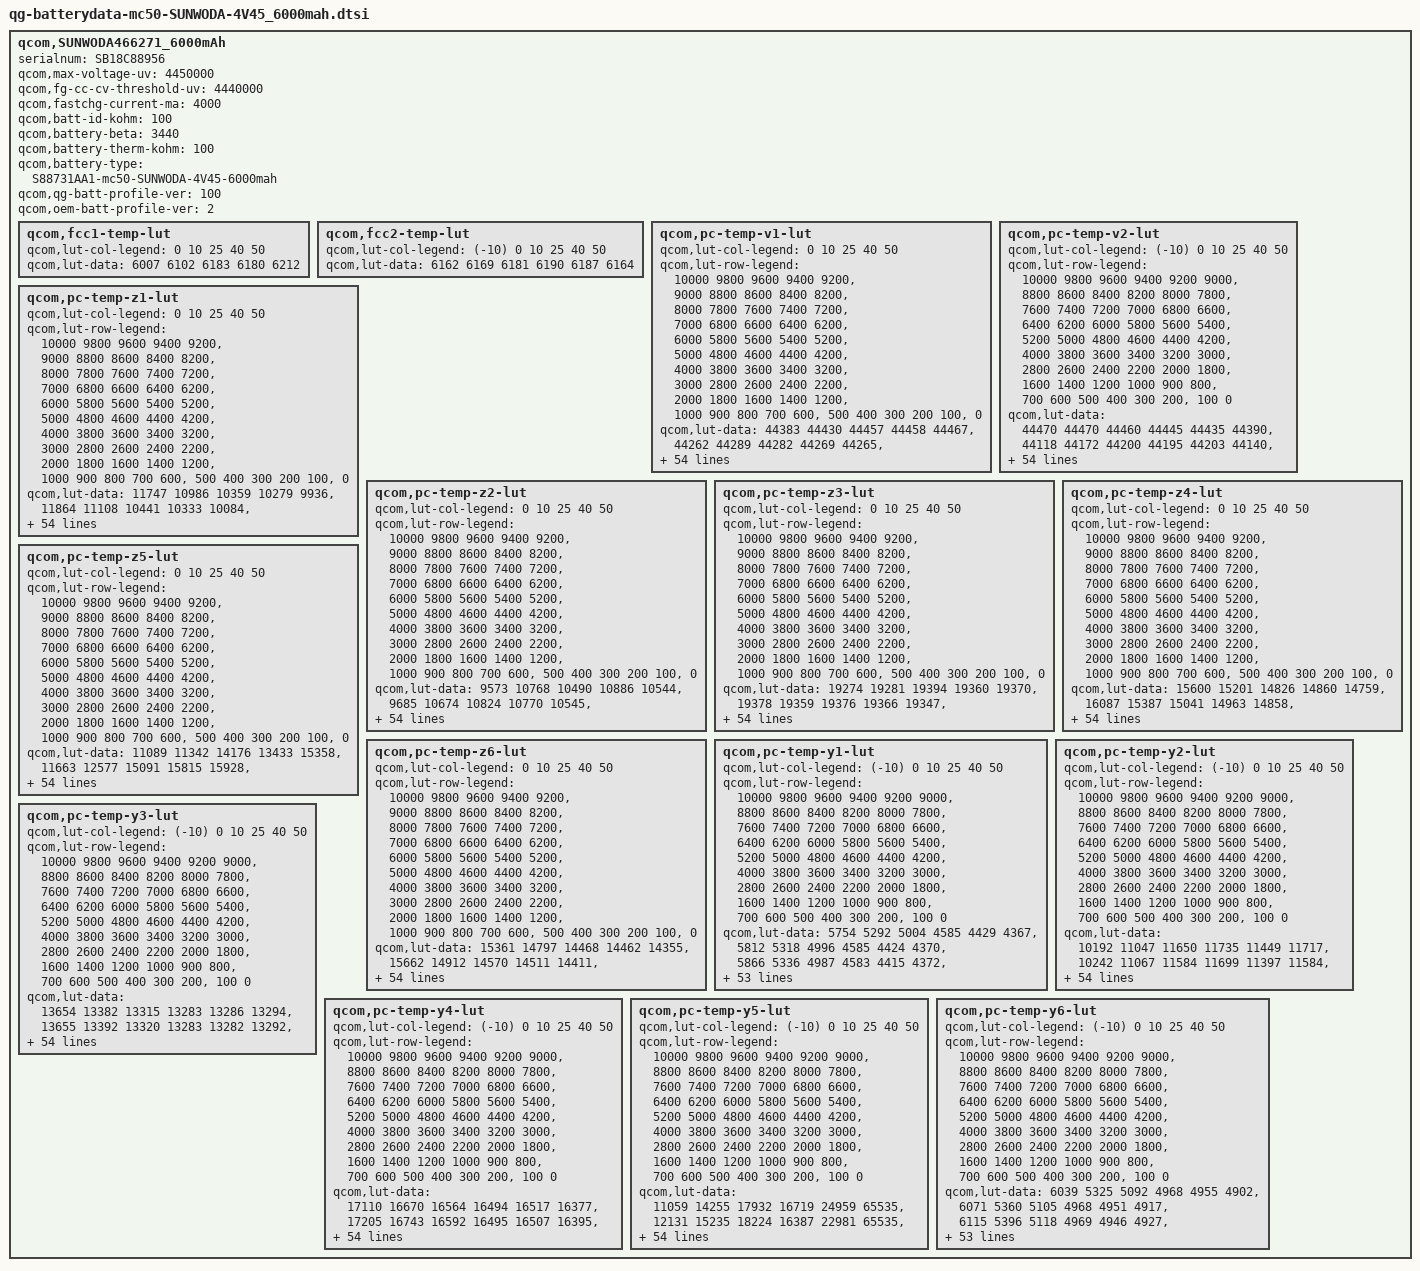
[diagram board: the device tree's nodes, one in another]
qcom,SUNWODA466271_6000mAh {
	/* SUNWODA466271_6000mAh_averaged_MasterSlave_Sep1th2020 */
        serialnum = "SB18C88956";
	qcom,max-voltage-uv = <4450000>;
	qcom,fg-cc-cv-threshold-uv = <4440000>;
	qcom,fastchg-current-ma = <4000>;
	qcom,batt-id-kohm = <100>;
	qcom,battery-beta = <3440>;
	qcom,battery-therm-kohm = <100>; /* on sub-board 100K */
	qcom,battery-type = "S88731AA1-mc50-SUNWODA-4V45-6000mah";
	qcom,qg-batt-profile-ver = <100>;
	qcom,oem-batt-profile-ver = <2>;

	/*qcom,step-chg-ranges = <3500000  4000000  8000000
				4000001  4200000  6000000
				4200001  4400000  4000000>;
	qcom,ocv-based-step-chg;*/

	qcom,fcc1-temp-lut {
		qcom,lut-col-legend = <0 10 25 40 50>;
		qcom,lut-data = <6007 6102 6183 6180 6212>;
	};

	qcom,fcc2-temp-lut {
		qcom,lut-col-legend = <(-10) 0 10 25 40 50>;
		qcom,lut-data = <6162 6169 6181 6190 6187 6164>;
	};

	qcom,pc-temp-v1-lut {
		qcom,lut-col-legend = <0 10 25 40 50>;
		qcom,lut-row-legend = <10000 9800 9600 9400 9200>,
			<9000 8800 8600 8400 8200>,
			<8000 7800 7600 7400 7200>,
			<7000 6800 6600 6400 6200>,
			<6000 5800 5600 5400 5200>,
			<5000 4800 4600 4400 4200>,
			<4000 3800 3600 3400 3200>,
			<3000 2800 2600 2400 2200>,
			<2000 1800 1600 1400 1200>,
			<1000 900 800 700 600>,
			<500 400 300 200 100>,
			<0>;
		qcom,lut-data = <44383 44430 44457 44458 44467>,
			<44262 44289 44282 44269 44265>,
			<44084 44095 44108 44089 44077>,
			<43882 43879 43904 43887 43883>,
			<43634 43660 43688 43676 43682>,
			<43372 43433 43467 43459 43470>,
			<43115 43198 43237 43230 43248>,
			<42854 42952 42995 42992 43018>,
			<42597 42700 42742 42742 42779>,
			<42343 42448 42496 42497 42534>,
			<42093 42196 42264 42259 42283>,
			<41854 41949 42033 42019 42027>,
			<41621 41708 41795 41770 41780>,
			<41388 41471 41550 41520 41537>,
			<41154 41242 41308 41285 41304>,
			<40926 41018 41064 41063 41082>,
			<40703 40799 40833 40848 40867>,
			<40488 40583 40629 40637 40658>,
			<40284 40380 40439 40433 40454>,
			<40086 40197 40251 40240 40255>,
			<39904 40025 40068 40063 40071>,
			<39742 39844 39875 39855 39865>,
			<39593 39657 39653 39545 39563>,
			<39439 39452 39424 39237 39242>,
			<39283 39194 39185 39064 39069>,
			<39128 38935 38904 38948 38968>,
			<38971 38767 38771 38842 38872>,
			<38820 38645 38752 38739 38765>,
			<38692 38553 38736 38642 38659>,
			<38578 38485 38658 38547 38560>,
			<38487 38429 38523 38456 38466>,
			<38422 38375 38411 38368 38377>,
			<38371 38325 38311 38283 38293>,
			<38327 38279 38245 38205 38212>,
			<38292 38240 38238 38136 38133>,
			<38257 38199 38246 38075 38057>,
			<38221 38134 38217 38018 37988>,
			<38183 38048 38141 37968 37931>,
			<38130 38003 38046 37902 37860>,
			<38052 38032 37923 37785 37752>,
			<37955 38045 37782 37648 37626>,
			<37833 37950 37657 37537 37518>,
			<37685 37788 37530 37428 37413>,
			<37509 37611 37369 37272 37264>,
			<37353 37436 37214 37126 37106>,
			<37251 37302 37116 37037 37005>,
			<37205 37252 37084 37009 36976>,
			<37180 37216 37066 36988 36971>,
			<37145 37178 37045 36971 36964>,
			<37102 37140 37002 36923 36921>,
			<36936 36976 36804 36694 36645>,
			<36506 36562 36382 36262 36249>,
			<35920 35981 35805 35687 35696>,
			<35119 35182 35021 34907 34899>,
			<33851 33930 33805 33699 33673>,
			<30000 30000 30000 30000 30000>;
	};

	qcom,pc-temp-v2-lut {
		qcom,lut-col-legend = <(-10) 0 10 25 40 50>;
		qcom,lut-row-legend = <10000 9800 9600 9400 9200 9000>,
			<8800 8600 8400 8200 8000 7800>,
			<7600 7400 7200 7000 6800 6600>,
			<6400 6200 6000 5800 5600 5400>,
			<5200 5000 4800 4600 4400 4200>,
			<4000 3800 3600 3400 3200 3000>,
			<2800 2600 2400 2200 2000 1800>,
			<1600 1400 1200 1000 900 800>,
			<700 600 500 400 300 200>,
			<100 0>;
		qcom,lut-data = <44470 44470 44460 44445 44435 44390>,
			<44118 44172 44200 44195 44203 44140>,
			<43798 43902 43958 43959 43976 43906>,
			<43517 43668 43739 43742 43758 43692>,
			<43269 43466 43540 43543 43546 43497>,
			<43020 43251 43330 43333 43328 43288>,
			<42757 43005 43094 43101 43099 43048>,
			<42495 42743 42848 42859 42863 42797>,
			<42251 42468 42602 42613 42621 42551>,
			<42018 42180 42352 42361 42370 42306>,
			<41760 41929 42103 42111 42121 42063>,
			<41441 41720 41855 41866 41875 41822>,
			<41151 41515 41610 41622 41630 41584>,
			<40974 41285 41372 41382 41390 41349>,
			<40834 41040 41141 41146 41155 41117>,
			<40605 40813 40918 40917 40927 40889>,
			<40188 40607 40709 40695 40705 40661>,
			<39795 40384 40492 40480 40491 40445>,
			<39540 40094 40250 40280 40289 40256>,
			<39325 39781 39998 40079 40090 40076>,
			<39114 39525 39746 39847 39882 39875>,
			<38912 39304 39491 39587 39667 39651>,
			<38720 39104 39264 39346 39445 39424>,
			<38520 38917 39069 39127 39198 39185>,
			<38347 38746 38895 38934 38970 38962>,
			<38247 38589 38740 38781 38809 38800>,
			<38179 38445 38603 38652 38680 38672>,
			<38119 38307 38477 38534 38561 38553>,
			<38066 38164 38363 38425 38449 38440>,
			<38016 38045 38257 38324 38346 38335>,
			<37964 37976 38158 38228 38253 38237>,
			<37912 37924 38066 38138 38167 38146>,
			<37860 37877 37978 38062 38088 38061>,
			<37807 37835 37892 37997 38015 37984>,
			<37748 37791 37819 37931 37937 37905>,
			<37670 37740 37767 37851 37847 37818>,
			<37577 37681 37722 37768 37751 37726>,
			<37489 37618 37672 37687 37651 37628>,
			<37404 37548 37619 37605 37546 37518>,
			<37320 37468 37554 37531 37448 37418>,
			<37231 37374 37465 37469 37362 37335>,
			<37144 37263 37359 37389 37266 37273>,
			<37067 37124 37231 37260 37149 37181>,
			<36991 36999 37083 37080 37014 36986>,
			<36922 36890 36945 36938 36887 36936>,
			<36829 36780 36861 36930 36847 36900>,
			<36780 36724 36832 36906 36833 36830>,
			<36721 36671 36804 36860 36820 36857>,
			<36651 36601 36761 36830 36796 36774>,
			<36554 36502 36689 36764 36733 36720>,
			<36373 36327 36492 36542 36467 36443>,
			<36010 35976 36135 36055 35988 36019>,
			<35429 35419 35420 35423 35350 35393>,
			<34548 34570 34546 34543 34456 34559>,
			<33152 33180 33215 33173 33102 33064>,
			<28114 28058 28059 28146 29053 30892>;
	};

	qcom,pc-temp-z1-lut {
		qcom,lut-col-legend = <0 10 25 40 50>;
		qcom,lut-row-legend = <10000 9800 9600 9400 9200>,
			<9000 8800 8600 8400 8200>,
			<8000 7800 7600 7400 7200>,
			<7000 6800 6600 6400 6200>,
			<6000 5800 5600 5400 5200>,
			<5000 4800 4600 4400 4200>,
			<4000 3800 3600 3400 3200>,
			<3000 2800 2600 2400 2200>,
			<2000 1800 1600 1400 1200>,
			<1000 900 800 700 600>,
			<500 400 300 200 100>,
			<0>;
		qcom,lut-data = <11747 10986 10359 10279 9936>,
			<11864 11108 10441 10333 10084>,
			<12136 11118 10449 10302 10095>,
			<12180 11129 10440 10241 10082>,
			<12032 11126 10428 10201 10076>,
			<11893 11111 10415 10176 10072>,
			<11837 11093 10401 10162 10060>,
			<11798 11070 10393 10163 10051>,
			<11796 11048 10386 10169 10033>,
			<11831 11032 10390 10167 10019>,
			<11861 11019 10613 10150 10032>,
			<11864 11005 10843 10136 10060>,
			<11856 10989 10806 10131 10055>,
			<11833 10977 10689 10127 10021>,
			<11742 10973 10656 10121 10000>,
			<11672 10972 10699 10109 9997>,
			<11663 10970 10746 10098 9996>,
			<11658 10962 10769 10089 9996>,
			<11647 10956 10787 10083 9997>,
			<11617 10958 10807 10084 10002>,
			<11596 10962 10832 10089 10042>,
			<11595 10965 10843 10095 10073>,
			<11596 10969 10789 10101 10058>,
			<11599 10971 10720 10109 10028>,
			<11606 10976 10733 10120 10014>,
			<11611 10982 10798 10135 10005>,
			<11618 10985 10826 10140 10002>,
			<11628 10989 10825 10137 10003>,
			<11631 10992 10823 10133 10007>,
			<11634 10991 10742 10128 10011>,
			<11636 10989 10564 10123 10017>,
			<11639 10991 10540 10127 10028>,
			<11642 10998 10749 10146 10058>,
			<11644 11005 10903 10158 10082>,
			<11655 11012 10883 10155 10078>,
			<11662 11022 10831 10146 10066>,
			<11661 11145 10756 10137 10065>,
			<11661 11453 10628 10123 10072>,
			<11666 11590 10530 10119 10082>,
			<11697 11618 10471 10124 10107>,
			<11720 11638 10436 10128 10134>,
			<11717 11655 10439 10130 10137>,
			<11712 11672 10450 10130 10134>,
			<11722 11748 10460 10132 10159>,
			<11719 11779 10472 10136 10187>,
			<11758 11744 10479 10139 10183>,
			<11722 11744 10482 10139 10178>,
			<11727 11750 10478 10139 10200>,
			<11733 11717 10481 10143 10168>,
			<11719 11718 10493 10146 10176>,
			<11757 11728 10500 10151 10202>,
			<11779 11766 10512 10156 10232>,
			<11799 11776 10527 10164 10192>,
			<11811 11762 10540 10175 10215>,
			<11811 11762 10540 10175 10215>,
			<11811 11762 10540 10175 10215>;
	};

	qcom,pc-temp-z2-lut {
		qcom,lut-col-legend = <0 10 25 40 50>;
		qcom,lut-row-legend = <10000 9800 9600 9400 9200>,
			<9000 8800 8600 8400 8200>,
			<8000 7800 7600 7400 7200>,
			<7000 6800 6600 6400 6200>,
			<6000 5800 5600 5400 5200>,
			<5000 4800 4600 4400 4200>,
			<4000 3800 3600 3400 3200>,
			<3000 2800 2600 2400 2200>,
			<2000 1800 1600 1400 1200>,
			<1000 900 800 700 600>,
			<500 400 300 200 100>,
			<0>;
		qcom,lut-data = <9573 10768 10490 10886 10544>,
			<9685 10674 10824 10770 10545>,
			<10140 10728 12942 10793 10654>,
			<10378 10795 11646 10751 10699>,
			<10510 10782 10809 10738 10714>,
			<10609 10710 10747 10715 10666>,
			<10682 10646 10687 10667 10574>,
			<10742 10594 10631 10622 10528>,
			<10783 10560 10573 10570 10492>,
			<10813 10558 10556 10554 10473>,
			<10820 10560 10617 10559 10489>,
			<10757 10563 10684 10569 10523>,
			<10658 10581 10682 10591 10535>,
			<10636 10602 10657 10622 10540>,
			<10641 10617 10657 10627 10541>,
			<10645 10632 10672 10616 10506>,
			<10632 10648 10685 10606 10459>,
			<10609 10666 10679 10598 10430>,
			<10608 10693 10662 10596 10396>,
			<10639 10882 10665 10602 10399>,
			<10664 11179 10679 10615 10513>,
			<10666 11206 10698 10635 10658>,
			<10664 10966 10785 10724 10803>,
			<10667 10820 10880 10825 10933>,
			<10674 10849 10849 10791 10893>,
			<10682 10882 10711 10632 10607>,
			<10695 10887 10651 10561 10453>,
			<10712 10883 10713 10583 10484>,
			<10730 10879 10796 10623 10526>,
			<10747 10873 10852 10708 10541>,
			<10762 10865 10910 10834 10550>,
			<10773 10867 10914 10885 10575>,
			<10782 10878 10792 10879 10702>,
			<10792 10888 10701 10865 10805>,
			<10805 10898 10763 10845 10774>,
			<10819 10906 10876 10806 10701>,
			<10836 10884 10939 10761 10648>,
			<10857 10803 10984 10710 10604>,
			<10879 10715 11008 10703 10585>,
			<10903 10610 11039 10815 10689>,
			<10931 10533 11071 10944 10833>,
			<10964 10519 11081 10959 10861>,
			<11010 10514 11098 10934 10867>,
			<11085 10498 11100 10934 10793>,
			<11469 10467 11132 10936 10721>,
			<11438 10434 11224 10835 10794>,
			<11587 10452 11204 10799 10769>,
			<11129 10504 11188 10750 10772>,
			<11108 10497 11204 10772 10805>,
			<10988 10828 11264 10909 11011>,
			<11012 10606 11266 10866 10768>,
			<10871 10613 11249 10625 10724>,
			<10708 10444 11127 10521 10775>,
			<10364 10413 11151 10497 10758>,
			<10364 10413 11151 10497 10758>,
			<10364 10413 11151 10497 10758>;
	};

	qcom,pc-temp-z3-lut {
		qcom,lut-col-legend = <0 10 25 40 50>;
		qcom,lut-row-legend = <10000 9800 9600 9400 9200>,
			<9000 8800 8600 8400 8200>,
			<8000 7800 7600 7400 7200>,
			<7000 6800 6600 6400 6200>,
			<6000 5800 5600 5400 5200>,
			<5000 4800 4600 4400 4200>,
			<4000 3800 3600 3400 3200>,
			<3000 2800 2600 2400 2200>,
			<2000 1800 1600 1400 1200>,
			<1000 900 800 700 600>,
			<500 400 300 200 100>,
			<0>;
		qcom,lut-data = <19274 19281 19394 19360 19370>,
			<19378 19359 19376 19366 19347>,
			<19504 19454 19379 19396 19374>,
			<19604 19540 19424 19410 19401>,
			<19705 19576 19456 19422 19418>,
			<19760 19598 19466 19436 19419>,
			<19736 19606 19473 19444 19420>,
			<19685 19607 19475 19444 19419>,
			<19657 19608 19476 19441 19413>,
			<19631 19608 19479 19435 19408>,
			<19618 19606 19500 19417 19410>,
			<19641 19604 19519 19404 19414>,
			<19682 19593 19514 19406 19411>,
			<19693 19578 19504 19410 19401>,
			<19688 19563 19493 19407 19391>,
			<19686 19547 19481 19396 19384>,
			<19700 19538 19473 19386 19377>,
			<19719 19534 19486 19380 19371>,
			<19722 19529 19511 19376 19364>,
			<19713 19519 19517 19372 19362>,
			<19703 19509 19517 19367 19365>,
			<19699 19508 19517 19365 19368>,
			<19696 19514 19502 19374 19372>,
			<19696 19522 19483 19383 19375>,
			<19697 19535 19488 19381 19372>,
			<19699 19548 19511 19367 19353>,
			<19700 19549 19518 19358 19340>,
			<19701 19546 19507 19353 19336>,
			<19701 19541 19493 19350 19334>,
			<19697 19535 19467 19354 19335>,
			<19692 19528 19430 19366 19340>,
			<19686 19524 19426 19377 19347>,
			<19677 19520 19469 19390 19366>,
			<19669 19518 19502 19396 19380>,
			<19661 19517 19496 19392 19379>,
			<19653 19517 19481 19384 19374>,
			<19646 19542 19460 19373 19367>,
			<19639 19610 19427 19358 19358>,
			<19632 19627 19409 19352 19352>,
			<19625 19530 19406 19359 19352>,
			<19618 19438 19404 19366 19351>,
			<19605 19431 19401 19363 19348>,
			<19588 19427 19397 19356 19339>,
			<19571 19422 19393 19357 19333>,
			<19509 19395 19387 19357 19330>,
			<19376 19349 19368 19344 19341>,
			<19380 19347 19366 19338 19349>,
			<19304 19338 19359 19336 19334>,
			<19297 19337 19356 19327 19325>,
			<19295 19292 19355 19319 19315>,
			<19296 19328 19343 19327 19342>,
			<19307 19323 19342 19352 19331>,
			<19312 19296 19339 19353 19324>,
			<19314 19301 19328 19343 19331>,
			<19314 19301 19328 19343 19331>,
			<19314 19301 19328 19343 19331>;
	};

	qcom,pc-temp-z4-lut {
		qcom,lut-col-legend = <0 10 25 40 50>;
		qcom,lut-row-legend = <10000 9800 9600 9400 9200>,
			<9000 8800 8600 8400 8200>,
			<8000 7800 7600 7400 7200>,
			<7000 6800 6600 6400 6200>,
			<6000 5800 5600 5400 5200>,
			<5000 4800 4600 4400 4200>,
			<4000 3800 3600 3400 3200>,
			<3000 2800 2600 2400 2200>,
			<2000 1800 1600 1400 1200>,
			<1000 900 800 700 600>,
			<500 400 300 200 100>,
			<0>;
		qcom,lut-data = <15600 15201 14826 14860 14759>,
			<16087 15387 15041 14963 14858>,
			<16393 15376 15077 14924 14912>,
			<16409 15352 15010 14888 14872>,
			<16100 15295 14938 14844 14828>,
			<15791 15170 14884 14798 14801>,
			<15642 15068 14838 14763 14771>,
			<15531 15001 14804 14744 14746>,
			<15475 14946 14776 14729 14720>,
			<15449 14897 14765 14720 14706>,
			<15421 14856 14837 14715 14705>,
			<15338 14822 14914 14711 14704>,
			<15212 14792 14876 14700 14702>,
			<15116 14771 14780 14687 14695>,
			<15038 14763 14752 14683 14689>,
			<14973 14758 14788 14681 14686>,
			<14920 14753 14816 14679 14682>,
			<14876 14747 14789 14675 14678>,
			<14846 14741 14742 14672 14673>,
			<14823 14733 14731 14669 14670>,
			<14804 14724 14729 14666 14667>,
			<14787 14721 14728 14667 14666>,
			<14773 14716 14734 14717 14710>,
			<14765 14714 14745 14783 14781>,
			<14758 14744 14777 14797 14797>,
			<14754 14790 14857 14801 14796>,
			<14761 14803 14887 14801 14793>,
			<14774 14807 14833 14794 14787>,
			<14783 14809 14775 14781 14778>,
			<14792 14802 14762 14761 14766>,
			<14797 14789 14752 14733 14750>,
			<14795 14779 14752 14711 14731>,
			<14790 14769 14806 14692 14701>,
			<14784 14759 14845 14681 14680>,
			<14775 14748 14801 14679 14676>,
			<14766 14739 14730 14680 14674>,
			<14756 14758 14704 14679 14675>,
			<14746 14827 14692 14675 14677>,
			<14737 14885 14688 14674 14683>,
			<14728 14935 14696 14684 14702>,
			<14723 14965 14706 14696 14723>,
			<14722 14960 14705 14695 14725>,
			<14721 14944 14701 14691 14724>,
			<14711 14921 14698 14689 14734>,
			<14708 14873 14687 14682 14739>,
			<14780 14836 14667 14665 14694>,
			<14777 14832 14661 14665 14676>,
			<14854 14835 14656 14656 14679>,
			<14854 14828 14645 14646 14658>,
			<14851 14869 14639 14642 14657>,
			<14845 14824 14668 14661 14684>,
			<14853 14844 14687 14657 14709>,
			<14859 14892 14694 14661 14701>,
			<14875 14906 14710 14675 14702>,
			<14875 14906 14710 14675 14702>,
			<14875 14906 14710 14675 14702>;
	};

	qcom,pc-temp-z5-lut {
		qcom,lut-col-legend = <0 10 25 40 50>;
		qcom,lut-row-legend = <10000 9800 9600 9400 9200>,
			<9000 8800 8600 8400 8200>,
			<8000 7800 7600 7400 7200>,
			<7000 6800 6600 6400 6200>,
			<6000 5800 5600 5400 5200>,
			<5000 4800 4600 4400 4200>,
			<4000 3800 3600 3400 3200>,
			<3000 2800 2600 2400 2200>,
			<2000 1800 1600 1400 1200>,
			<1000 900 800 700 600>,
			<500 400 300 200 100>,
			<0>;
		qcom,lut-data = <11089 11342 14176 13433 15358>,
			<11663 12577 15091 15815 15928>,
			<12285 14143 15214 17788 17868>,
			<12926 15699 16884 19101 20347>,
			<13978 16572 18321 20930 22136>,
			<14697 17179 19178 23608 23023>,
			<14743 17706 19953 25865 24031>,
			<14679 18133 20748 26956 24636>,
			<14617 18601 21561 27902 25798>,
			<14421 19426 21860 28092 26287>,
			<14382 20628 20465 25535 26549>,
			<14922 21700 19020 23852 27440>,
			<15861 22822 19911 27135 28520>,
			<16630 23631 22080 32107 29813>,
			<17273 23738 22593 32567 30384>,
			<18103 23657 21201 30056 29094>,
			<19756 24077 20105 28402 27450>,
			<22003 25415 22257 28509 27379>,
			<23723 26328 26126 29440 27958>,
			<25095 24929 27142 29974 29200>,
			<26479 22483 27328 30371 32268>,
			<27838 23078 27965 31229 35977>,
			<29352 30601 36584 37684 40695>,
			<32010 40259 47214 44699 45188>,
			<37394 53699 47957 41809 42964>,
			<43278 65535 44061 30032 29220>,
			<48986 65535 40154 22982 20428>,
			<54170 59200 36532 20404 18574>,
			<56195 51673 33491 19166 17601>,
			<56794 45764 30918 19637 17401>,
			<56449 41073 27595 21302 17591>,
			<54313 38963 25261 24689 18482>,
			<50939 37611 24022 33541 23364>,
			<48321 37246 24189 39389 28949>,
			<46041 38322 28088 38358 32773>,
			<44597 39704 33559 35322 35769>,
			<43844 40271 34721 32470 35739>,
			<43236 40499 33461 29494 32653>,
			<43565 40120 32724 28637 30609>,
			<46146 34874 35190 37808 30443>,
			<47922 30046 38141 47826 30308>,
			<45173 29280 36811 41801 27442>,
			<41971 28083 32931 27592 20664>,
			<42800 27569 32510 28527 20167>,
			<37442 27427 33098 29828 21592>,
			<20326 24126 30903 26426 31907>,
			<19766 24110 30244 23348 36980>,
			<13545 19630 27233 24100 28213>,
			<13265 19408 28252 22868 30140>,
			<13235 13560 29712 21906 29154>,
			<13429 18054 22366 21739 39991>,
			<13614 15794 18313 22976 23698>,
			<13456 13177 17079 21279 19194>,
			<13165 12975 15271 17108 27119>,
			<13165 12975 15271 17108 27119>,
			<13165 12975 15271 17108 27119>;
	};

	qcom,pc-temp-z6-lut {
		qcom,lut-col-legend = <0 10 25 40 50>;
		qcom,lut-row-legend = <10000 9800 9600 9400 9200>,
			<9000 8800 8600 8400 8200>,
			<8000 7800 7600 7400 7200>,
			<7000 6800 6600 6400 6200>,
			<6000 5800 5600 5400 5200>,
			<5000 4800 4600 4400 4200>,
			<4000 3800 3600 3400 3200>,
			<3000 2800 2600 2400 2200>,
			<2000 1800 1600 1400 1200>,
			<1000 900 800 700 600>,
			<500 400 300 200 100>,
			<0>;
		qcom,lut-data = <15361 14797 14468 14462 14355>,
			<15662 14912 14570 14511 14411>,
			<16006 14949 14584 14502 14449>,
			<16051 14967 14574 14482 14443>,
			<15819 14953 14563 14464 14435>,
			<15582 14899 14546 14448 14427>,
			<15445 14850 14524 14436 14413>,
			<15331 14814 14510 14429 14399>,
			<15285 14783 14498 14422 14382>,
			<15270 14756 14494 14414 14372>,
			<15257 14731 14588 14400 14373>,
			<15228 14709 14685 14389 14380>,
			<15187 14686 14655 14384 14376>,
			<15138 14667 14575 14380 14363>,
			<15066 14654 14551 14374 14351>,
			<15012 14643 14571 14366 14345>,
			<14992 14635 14589 14358 14339>,
			<14978 14629 14590 14351 14333>,
			<14963 14623 14589 14346 14327>,
			<14943 14615 14591 14343 14325>,
			<14927 14607 14598 14340 14330>,
			<14918 14605 14602 14339 14337>,
			<14911 14607 14582 14367 14358>,
			<14909 14610 14557 14402 14384>,
			<14909 14630 14576 14406 14386>,
			<14910 14658 14641 14404 14375>,
			<14915 14664 14666 14401 14365>,
			<14923 14666 14644 14394 14361>,
			<14926 14666 14607 14386 14357>,
			<14927 14661 14556 14379 14353>,
			<14927 14652 14493 14373 14350>,
			<14925 14646 14488 14371 14348>,
			<14921 14641 14589 14372 14350>,
			<14917 14637 14662 14372 14352>,
			<14912 14634 14637 14368 14348>,
			<14906 14632 14583 14363 14343>,
			<14899 14697 14533 14355 14339>,
			<14892 14876 14478 14343 14337>,
			<14890 14940 14447 14338 14336>,
			<14889 14927 14438 14346 14346>,
			<14889 14915 14433 14355 14360>,
			<14889 14920 14431 14353 14360>,
			<14889 14933 14429 14347 14354>,
			<14881 14943 14427 14348 14360>,
			<14851 14933 14422 14345 14364>,
			<14830 14909 14405 14331 14349>,
			<14830 14903 14402 14328 14346>,
			<14826 14896 14396 14323 14342>,
			<14821 14891 14391 14314 14323>,
			<14822 14892 14388 14308 14319>,
			<14829 14898 14396 14322 14349>,
			<14848 14911 14407 14335 14360>,
			<14862 14924 14413 14340 14347>,
			<14889 14945 14418 14344 14356>,
			<14889 14945 14418 14344 14356>,
			<14889 14945 14418 14344 14356>;
	};

	qcom,pc-temp-y1-lut {
		qcom,lut-col-legend = <(-10) 0 10 25 40 50>;
		qcom,lut-row-legend = <10000 9800 9600 9400 9200 9000>,
			<8800 8600 8400 8200 8000 7800>,
			<7600 7400 7200 7000 6800 6600>,
			<6400 6200 6000 5800 5600 5400>,
			<5200 5000 4800 4600 4400 4200>,
			<4000 3800 3600 3400 3200 3000>,
			<2800 2600 2400 2200 2000 1800>,
			<1600 1400 1200 1000 900 800>,
			<700 600 500 400 300 200>,
			<100 0>;
		qcom,lut-data = <5754 5292 5004 4585 4429 4367>,
			<5812 5318 4996 4585 4424 4370>,
			<5866 5336 4987 4583 4415 4372>,
			<5911 5346 4978 4581 4405 4373>,
			<5940 5352 4972 4578 4397 4373>,
			<5949 5353 4968 4575 4392 4373>,
			<5934 5346 4968 4570 4388 4345>,
			<5916 5336 4967 4566 4385 4311>,
			<5923 5359 4963 4562 4384 4306>,
			<5946 5439 4954 4558 4383 4303>,
			<5954 5465 4947 4555 4382 4303>,
			<5930 5399 4942 4553 4379 4303>,
			<5908 5335 4938 4552 4376 4304>,
			<5917 5330 4937 4550 4374 4311>,
			<5937 5327 4936 4549 4372 4327>,
			<5941 5326 4935 4548 4372 4335>,
			<5928 5328 4932 4549 4371 4338>,
			<5917 5330 4931 4550 4370 4341>,
			<5914 5332 4933 4549 4370 4343>,
			<5915 5336 4937 4549 4371 4345>,
			<5916 5339 4937 4548 4371 4346>,
			<5920 5340 4937 4547 4371 4346>,
			<5921 5342 4937 4547 4371 4346>,
			<5928 5346 4939 4549 4371 4345>,
			<5934 5349 4942 4552 4371 4343>,
			<5923 5350 4944 4554 4372 4338>,
			<5898 5351 4947 4556 4372 4325>,
			<5876 5351 4949 4558 4373 4320>,
			<5850 5353 4953 4560 4375 4325>,
			<5819 5354 4955 4563 4378 4331>,
			<5796 5355 4956 4566 4380 4339>,
			<5780 5357 4956 4569 4382 4349>,
			<5759 5358 4960 4573 4384 4352>,
			<5725 5364 4972 4580 4385 4352>,
			<5703 5369 4979 4590 4387 4352>,
			<5746 5365 4977 4721 4390 4349>,
			<5828 5357 4973 4884 4392 4343>,
			<5855 5355 4974 4849 4393 4342>,
			<5862 5354 4976 4673 4394 4344>,
			<5864 5354 4980 4605 4394 4344>,
			<5863 5360 4987 4700 4396 4346>,
			<5863 5364 4994 4816 4397 4349>,
			<5866 5362 4999 4924 4398 4375>,
			<5855 5356 5014 4638 4397 4423>,
			<5860 5358 5020 4609 4401 4396>,
			<5843 5451 5020 4790 4403 4423>,
			<5848 5493 5019 4886 4404 4435>,
			<5858 5502 5028 4945 4404 4428>,
			<5836 5479 5017 4731 4402 4420>,
			<5844 5476 5028 4624 4403 4446>,
			<5846 5502 5035 4619 4404 4453>,
			<5866 5497 5036 4630 4410 4443>,
			<5886 5374 5175 4642 4414 4410>,
			<5995 5413 5272 4659 4422 4419>,
			<5995 5413 5272 4659 4422 4419>,
			<5995 5413 5272 4659 4422 4419>;
	};

	qcom,pc-temp-y2-lut {
		qcom,lut-col-legend = <(-10) 0 10 25 40 50>;
		qcom,lut-row-legend = <10000 9800 9600 9400 9200 9000>,
			<8800 8600 8400 8200 8000 7800>,
			<7600 7400 7200 7000 6800 6600>,
			<6400 6200 6000 5800 5600 5400>,
			<5200 5000 4800 4600 4400 4200>,
			<4000 3800 3600 3400 3200 3000>,
			<2800 2600 2400 2200 2000 1800>,
			<1600 1400 1200 1000 900 800>,
			<700 600 500 400 300 200>,
			<100 0>;
		qcom,lut-data = <10192 11047 11650 11735 11449 11717>,
			<10242 11067 11584 11699 11397 11584>,
			<10330 11085 11519 11656 11341 11386>,
			<10427 11099 11457 11607 11284 11178>,
			<10505 11107 11401 11552 11231 11016>,
			<10535 11107 11352 11493 11184 10957>,
			<10536 11096 11303 11414 11137 10969>,
			<10536 11079 11266 11350 11098 10984>,
			<10578 11062 11248 11337 11075 10971>,
			<10692 11039 11236 11340 11051 10937>,
			<10746 11014 11234 11342 11044 10916>,
			<10757 10977 11241 11337 11053 10899>,
			<10765 10952 11252 11329 11059 10889>,
			<10783 11050 11279 11311 11038 10902>,
			<10816 11262 11327 11288 10998 10930>,
			<10815 11324 11377 11288 10985 10957>,
			<10609 11274 11438 11321 10983 11054>,
			<10450 11239 11479 11369 10989 11125>,
			<10202 11278 11493 11467 11057 11096>,
			<9802 11338 11505 11566 11176 11051>,
			<9711 11373 11518 11567 11285 11067>,
			<9700 11402 11532 11530 11400 11108>,
			<9692 11422 11551 11516 11440 11135>,
			<9683 11445 11587 11561 11362 11193>,
			<9677 11467 11630 11624 11272 11264>,
			<9673 11476 11669 11668 11293 11291>,
			<9670 11492 11709 11708 11387 11338>,
			<9668 11506 11740 11738 11425 11379>,
			<9668 11524 11769 11772 11457 11459>,
			<9668 11535 11789 11792 11480 11527>,
			<9669 11517 11797 11819 11479 11504>,
			<9670 11457 11802 11865 11478 11429>,
			<9671 11327 11802 11875 11495 11387>,
			<9672 10926 11803 11879 11556 11427>,
			<9672 10578 11797 11877 11595 11458>,
			<9669 10257 11770 11827 11612 11457>,
			<9662 9869 11725 11767 11627 11469>,
			<9660 9746 11669 11774 11612 11459>,
			<9660 9704 11592 11818 11548 11432>,
			<9659 9684 11505 11833 11512 11424>,
			<9659 9675 11404 11762 11578 11374>,
			<9659 9670 11288 11639 11601 11344>,
			<9659 9666 11156 11406 11476 11563>,
			<9659 9664 10999 11687 11436 11401>,
			<9659 9663 10987 11760 11439 11568>,
			<9658 9661 10851 11582 11324 11242>,
			<9658 9659 10784 11336 11263 10968>,
			<9658 9659 10724 10561 11367 12711>,
			<9657 9658 10667 11246 11184 11253>,
			<9657 9658 10612 11495 11264 11022>,
			<9656 9657 10566 11507 11194 11370>,
			<9654 9656 10414 11389 11188 12540>,
			<9652 9655 9729 11314 11048 12247>,
			<9651 9653 9662 11164 10951 11058>,
			<9651 9653 9662 11164 10951 11058>,
			<9651 9653 9662 11164 10951 11058>;
	};

	qcom,pc-temp-y3-lut {
		qcom,lut-col-legend = <(-10) 0 10 25 40 50>;
		qcom,lut-row-legend = <10000 9800 9600 9400 9200 9000>,
			<8800 8600 8400 8200 8000 7800>,
			<7600 7400 7200 7000 6800 6600>,
			<6400 6200 6000 5800 5600 5400>,
			<5200 5000 4800 4600 4400 4200>,
			<4000 3800 3600 3400 3200 3000>,
			<2800 2600 2400 2200 2000 1800>,
			<1600 1400 1200 1000 900 800>,
			<700 600 500 400 300 200>,
			<100 0>;
		qcom,lut-data = <13654 13382 13315 13283 13286 13294>,
			<13655 13392 13320 13283 13282 13292>,
			<13658 13402 13325 13283 13280 13289>,
			<13661 13411 13331 13284 13278 13286>,
			<13664 13418 13336 13285 13278 13283>,
			<13665 13421 13338 13286 13278 13281>,
			<13665 13420 13339 13286 13280 13279>,
			<13665 13419 13340 13287 13282 13278>,
			<13664 13427 13342 13287 13283 13278>,
			<13663 13451 13344 13287 13283 13280>,
			<13655 13459 13345 13287 13284 13282>,
			<13562 13451 13344 13291 13284 13283>,
			<13478 13439 13342 13294 13285 13284>,
			<13487 13427 13341 13294 13284 13284>,
			<13512 13414 13340 13294 13284 13285>,
			<13516 13403 13339 13295 13284 13286>,
			<13492 13393 13340 13298 13285 13287>,
			<13471 13386 13340 13300 13286 13289>,
			<13462 13381 13338 13301 13288 13292>,
			<13456 13376 13334 13302 13290 13295>,
			<13458 13371 13330 13302 13291 13294>,
			<13465 13366 13325 13299 13291 13289>,
			<13469 13361 13321 13295 13291 13285>,
			<13451 13356 13318 13289 13285 13282>,
			<13428 13352 13315 13285 13280 13279>,
			<13435 13347 13312 13284 13279 13278>,
			<13469 13343 13311 13284 13279 13279>,
			<13494 13337 13310 13284 13279 13279>,
			<13511 13326 13310 13286 13278 13277>,
			<13528 13316 13310 13287 13277 13275>,
			<13548 13315 13309 13287 13277 13276>,
			<13572 13317 13307 13286 13278 13279>,
			<13604 13319 13305 13286 13278 13281>,
			<13645 13326 13304 13288 13278 13281>,
			<13687 13333 13304 13289 13278 13280>,
			<13779 13342 13304 13293 13278 13278>,
			<13937 13359 13305 13297 13279 13275>,
			<14066 13381 13307 13296 13278 13273>,
			<14180 13418 13312 13289 13277 13272>,
			<14262 13462 13317 13287 13277 13271>,
			<14310 13511 13320 13292 13278 13271>,
			<14349 13564 13323 13299 13278 13272>,
			<14388 13619 13328 13310 13278 13288>,
			<14406 13690 13328 13289 13278 13286>,
			<14331 13671 13324 13282 13275 13278>,
			<14431 14050 13332 13294 13280 13275>,
			<14498 14281 13338 13310 13283 13285>,
			<14588 14329 13348 13332 13287 13307>,
			<14710 14372 13360 13318 13290 13297>,
			<14870 14434 13377 13301 13290 13280>,
			<15107 14536 13389 13300 13284 13297>,
			<15705 14744 13405 13293 13284 13298>,
			<17445 14720 13715 13301 13286 13330>,
			<22060 15778 14633 13311 13291 13303>,
			<22060 15778 14633 13311 13291 13303>,
			<22060 15778 14633 13311 13291 13303>;
	};

	qcom,pc-temp-y4-lut {
		qcom,lut-col-legend = <(-10) 0 10 25 40 50>;
		qcom,lut-row-legend = <10000 9800 9600 9400 9200 9000>,
			<8800 8600 8400 8200 8000 7800>,
			<7600 7400 7200 7000 6800 6600>,
			<6400 6200 6000 5800 5600 5400>,
			<5200 5000 4800 4600 4400 4200>,
			<4000 3800 3600 3400 3200 3000>,
			<2800 2600 2400 2200 2000 1800>,
			<1600 1400 1200 1000 900 800>,
			<700 600 500 400 300 200>,
			<100 0>;
		qcom,lut-data = <17110 16670 16564 16494 16517 16377>,
			<17205 16743 16592 16495 16507 16395>,
			<17376 16861 16627 16496 16494 16420>,
			<17565 16987 16660 16498 16481 16445>,
			<17713 17084 16685 16500 16471 16464>,
			<17763 17117 16693 16502 16467 16470>,
			<17757 17108 16688 16505 16466 16467>,
			<17745 17096 16681 16508 16466 16463>,
			<17725 17105 16677 16512 16468 16464>,
			<17696 17149 16674 16518 16470 16465>,
			<17691 17195 16674 16521 16473 16468>,
			<17772 17248 16682 16523 16476 16473>,
			<17848 17286 16695 16525 16480 16479>,
			<17849 17262 16712 16533 16486 16487>,
			<17835 17196 16737 16546 16492 16495>,
			<17776 17181 16767 16558 16499 16498>,
			<17495 17204 16812 16570 16506 16492>,
			<17263 17212 16836 16586 16515 16489>,
			<17216 17105 16818 16619 16528 16509>,
			<17186 16936 16780 16652 16542 16543>,
			<17127 16865 16734 16645 16557 16557>,
			<17028 16831 16669 16602 16574 16574>,
			<16944 16801 16622 16560 16578 16581>,
			<16879 16771 16595 16519 16526 16536>,
			<16836 16744 16578 16491 16471 16481>,
			<16836 16718 16572 16489 16467 16472>,
			<16846 16695 16569 16490 16466 16469>,
			<16853 16668 16568 16492 16467 16469>,
			<16858 16629 16568 16496 16472 16473>,
			<16863 16602 16568 16501 16480 16478>,
			<16866 16608 16568 16506 16487 16477>,
			<16868 16626 16567 16512 16495 16466>,
			<16871 16645 16563 16521 16504 16466>,
			<16877 16674 16543 16537 16515 16471>,
			<16881 16704 16531 16546 16520 16475>,
			<16883 16736 16538 16543 16513 16484>,
			<16885 16774 16551 16539 16501 16501>,
			<16890 16799 16565 16531 16489 16502>,
			<16900 16820 16584 16517 16476 16494>,
			<16906 16828 16603 16513 16472 16489>,
			<16905 16829 16622 16520 16476 16514>,
			<16906 16828 16638 16534 16478 16541>,
			<16919 16816 16650 16567 16477 16506>,
			<16932 16810 16648 16517 16472 16412>,
			<16898 16791 16612 16480 16452 16505>,
			<16920 16821 16638 16525 16465 16530>,
			<16941 16860 16664 16564 16483 16448>,
			<16974 16903 16700 16645 16512 16495>,
			<17006 16957 16753 16649 16555 16487>,
			<17043 17021 16826 16606 16583 16562>,
			<17042 17074 16861 16576 16507 16417>,
			<17096 17082 16919 16532 16481 16470>,
			<17514 17088 16932 16545 16484 16429>,
			<20059 17380 17246 16574 16489 16541>,
			<20059 17380 17246 16574 16489 16541>,
			<20059 17380 17246 16574 16489 16541>;
	};

	qcom,pc-temp-y5-lut {
		qcom,lut-col-legend = <(-10) 0 10 25 40 50>;
		qcom,lut-row-legend = <10000 9800 9600 9400 9200 9000>,
			<8800 8600 8400 8200 8000 7800>,
			<7600 7400 7200 7000 6800 6600>,
			<6400 6200 6000 5800 5600 5400>,
			<5200 5000 4800 4600 4400 4200>,
			<4000 3800 3600 3400 3200 3000>,
			<2800 2600 2400 2200 2000 1800>,
			<1600 1400 1200 1000 900 800>,
			<700 600 500 400 300 200>,
			<100 0>;
		qcom,lut-data = <11059 14255 17932 16719 24959 65535>,
			<12131 15235 18224 16387 22981 65535>,
			<13154 15960 18338 15981 20640 59509>,
			<14099 16463 18317 15553 18425 41888>,
			<14936 16772 18204 15154 16823 27518>,
			<15637 16916 18041 14834 16321 20908>,
			<16175 16764 17707 14538 16807 18099>,
			<16681 16537 17338 14259 17296 16199>,
			<17411 16573 17152 13955 17111 16310>,
			<18284 16730 17011 13589 16729 17044>,
			<18419 16748 16747 13520 16346 17358>,
			<16261 16328 16024 13960 15966 17261>,
			<14271 15899 15358 14329 15574 17081>,
			<15923 15771 15086 14130 15101 16744>,
			<19591 15729 14904 13747 14631 16175>,
			<20296 16100 14910 13688 14456 15748>,
			<18173 17969 15229 13874 14426 15375>,
			<16400 19328 15762 14147 14426 15193>,
			<15983 19328 17298 14540 14525 16192>,
			<15808 19193 19261 15163 14816 17964>,
			<16006 19291 20033 16516 15906 18550>,
			<16545 19524 20456 19088 18639 18713>,
			<16802 19675 20577 20084 19804 18776>,
			<14898 19736 20218 18671 19379 19431>,
			<12475 19768 19754 17107 18895 20279>,
			<12124 19838 19550 16940 18790 20370>,
			<12059 20019 19400 17156 18749 19801>,
			<12047 19894 19438 17333 18507 18853>,
			<12125 17473 19822 18078 17486 16967>,
			<12244 15026 20197 18672 16705 15334>,
			<12343 14440 20382 18719 16695 16990>,
			<12448 14090 20559 18806 16823 22153>,
			<12597 14038 20517 19121 17017 23989>,
			<12864 14352 20168 20166 17324 23944>,
			<13037 14627 19781 20928 17767 23536>,
			<12977 14331 19304 20312 18927 21349>,
			<12857 13861 18913 19307 20122 17681>,
			<12823 13975 18978 19324 20146 16279>,
			<12819 14321 19193 19739 19761 15727>,
			<12818 14523 19067 19736 19490 15512>,
			<12702 14599 18287 19498 19359 16431>,
			<12540 14552 17632 18867 19109 19409>,
			<12437 13598 17247 16893 18438 65535>,
			<12355 13150 16480 17534 18800 65535>,
			<12492 12908 16544 17219 17645 54507>,
			<12499 12779 16161 16670 17053 56022>,
			<12552 12721 15956 16929 16511 65535>,
			<12534 12916 15988 14077 17131 65535>,
			<12656 13145 15964 15279 16593 65535>,
			<13015 13563 16363 16679 16366 29163>,
			<13226 14055 16695 17620 15893 65535>,
			<12293 13510 17345 16158 16589 65535>,
			<10782 12711 13639 17637 16435 65535>,
			<9501 11236 11997 19056 17768 65535>,
			<9501 11236 11997 19056 17768 65535>,
			<9501 11236 11997 19056 17768 65535>;
	};

	qcom,pc-temp-y6-lut {
		qcom,lut-col-legend = <(-10) 0 10 25 40 50>;
		qcom,lut-row-legend = <10000 9800 9600 9400 9200 9000>,
			<8800 8600 8400 8200 8000 7800>,
			<7600 7400 7200 7000 6800 6600>,
			<6400 6200 6000 5800 5600 5400>,
			<5200 5000 4800 4600 4400 4200>,
			<4000 3800 3600 3400 3200 3000>,
			<2800 2600 2400 2200 2000 1800>,
			<1600 1400 1200 1000 900 800>,
			<700 600 500 400 300 200>,
			<100 0>;
		qcom,lut-data = <6039 5325 5092 4968 4955 4902>,
			<6071 5360 5105 4968 4951 4917>,
			<6115 5396 5118 4969 4946 4927>,
			<6160 5428 5129 4970 4941 4933>,
			<6194 5450 5136 4971 4937 4936>,
			<6205 5456 5138 4971 4936 4937>,
			<6202 5449 5136 4972 4937 4932>,
			<6195 5438 5132 4973 4938 4927>,
			<6185 5460 5129 4973 4939 4927>,
			<6169 5529 5128 4975 4940 4929>,
			<6147 5552 5127 4976 4941 4930>,
			<6109 5526 5127 4978 4942 4933>,
			<6080 5492 5128 4981 4943 4935>,
			<6088 5464 5130 4984 4944 4939>,
			<6106 5438 5136 4987 4946 4944>,
			<6098 5432 5143 4991 4948 4945>,
			<6004 5431 5154 4996 4951 4945>,
			<5919 5426 5161 5002 4954 4945>,
			<5890 5394 5154 5013 4959 4952>,
			<5868 5344 5141 5022 4965 4965>,
			<5851 5324 5125 5020 4969 4969>,
			<5837 5313 5103 5005 4973 4971>,
			<5825 5305 5087 4990 4974 4968>,
			<5811 5297 5077 4974 4955 4952>,
			<5801 5291 5071 4963 4935 4934>,
			<5812 5285 5069 4963 4933 4930>,
			<5857 5281 5069 4963 4933 4929>,
			<5889 5276 5069 4963 4933 4928>,
			<5897 5267 5070 4966 4934 4929>,
			<5900 5260 5071 4968 4936 4929>,
			<5904 5266 5072 4970 4938 4930>,
			<5907 5286 5073 4972 4941 4931>,
			<5927 5309 5073 4975 4944 4932>,
			<5954 5339 5069 4980 4947 4933>,
			<5982 5375 5067 4986 4948 4934>,
			<6073 5415 5071 5022 4947 4935>,
			<6243 5460 5078 5065 4944 4937>,
			<6362 5514 5087 5052 4941 4936>,
			<6452 5580 5100 4999 4936 4933>,
			<6516 5646 5115 4978 4935 4931>,
			<6555 5710 5132 5000 4937 4938>,
			<6589 5772 5150 5045 4938 4947>,
			<6624 5829 5170 5138 4938 4954>,
			<6637 5897 5185 4991 4936 4926>,
			<6574 5882 5167 4966 4929 4946>,
			<6654 6206 5204 5027 4936 4953>,
			<6710 6411 5230 5115 4943 4939>,
			<6790 6467 5264 5232 4955 4964>,
			<6895 6517 5305 5076 4969 4957>,
			<7029 6584 5358 5019 4978 4969>,
			<7210 6685 5396 5009 4952 4940>,
			<7710 6856 5450 4992 4945 4955>,
			<9205 6820 5833 5005 4948 4962>,
			<13305 7738 6736 5024 4954 4977>,
			<13305 7738 6736 5024 4954 4977>,
			<13305 7738 6736 5024 4954 4977>;
	};

};
